# STM32WB55xx register map
File version: 1.0
Registers are 32-bit, read-write, reset 0x0 unless marked. A register's access mark holds for its fields unless they carry their own. Offsets are from the block's base; [hi:lo] are bit positions; {n}, {i} and the like mark numbered series.

## IPCC — Inter-Processor Communication
Base 0x58000C00
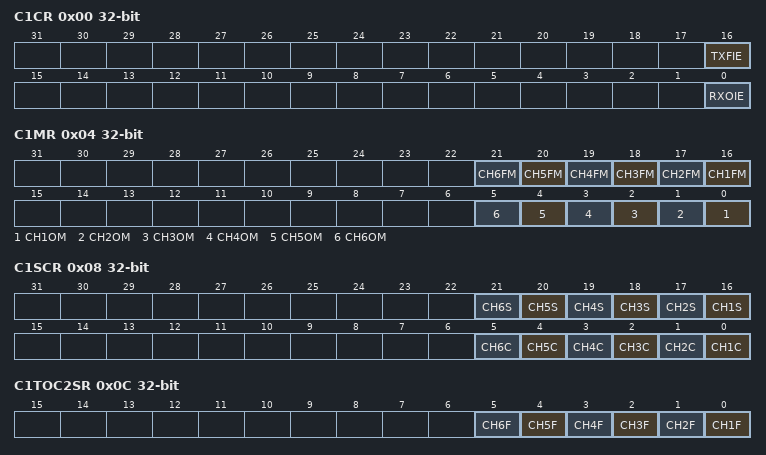
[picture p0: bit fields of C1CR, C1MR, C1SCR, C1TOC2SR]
0x00 C1CR — Inter-Processor Communication: C1 control register
  [16] TXFIE — Processor M4 Transmit channel free interrupt enable
  [0] RXOIE — Processor M4 Receive channel occupied interrupt enable
0x04 C1MR — Inter-Processor Communication: C1 mask register
  [n+15] CH{n}FM (n=1..6) — M4 Transmit Channel{n} free interrupt mask
  [n-1] CH{n}OM (n=1..6) — M4 Channel{n} occupied interrupt mask
0x08 C1SCR — Inter-Processor Communication: C1 status set clear register
  [n+15] CH{n}S (n=1..6) — M4 transmit Channel{n} status set
  [n-1] CH{n}C (n=1..6) — M4 receive Channel{n} status clear
0x0C C1TOC2SR — Inter-Processor Communication: C1 to processor M4 status register
  [n-1] CH{n}F (n=1..6) — M4 transmit to M4 receive Channel{n} status flag before masking
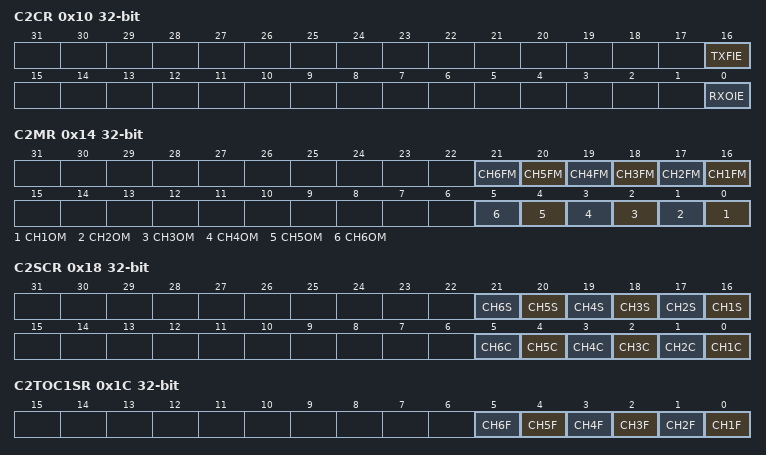
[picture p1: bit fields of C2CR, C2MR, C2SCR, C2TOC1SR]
0x10 C2CR — Inter-Processor Communication: C2 control register
  [16] TXFIE — Processor M0+ Transmit channel free interrupt enable
  [0] RXOIE — Processor M0+ Receive channel occupied interrupt enable
0x14 C2MR — Inter-Processor Communication: C2 mask register
  [n+15] CH{n}FM (n=1..6) — M0+ Transmit Channel{n} free interrupt mask
  [n-1] CH{n}OM (n=1..6) — M0+ Channel{n} occupied interrupt mask
0x18 C2SCR — Inter-Processor Communication: C2 status set clear register
  [n+15] CH{n}S (n=1..6) — M0+ transmit Channel{n} status set
  [n-1] CH{n}C (n=1..6) — M0+ receive Channel{n} status clear
0x1C C2TOC1SR — Inter-Processor Communication: C2 to processor M4 status register
  [n-1] CH{n}F (n=1..6) — M0+ transmit to M0 receive Channel{n} status flag before masking

## RNG
Base 0x58001000
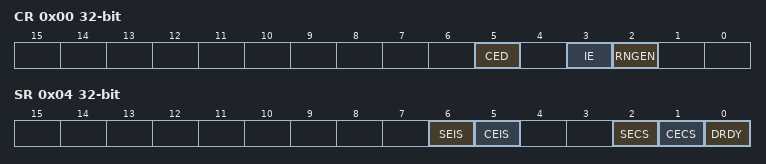
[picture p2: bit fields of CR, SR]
0x00 CR — RNG control register
  [5] CED, [3] IE, [2] RNGEN
0x04 SR — RNG status register
  [6] SEIS, [5] CEIS, [2] SECS, [1] CECS, [0] DRDY
0x08 DR — RNG data register

## HSEM — HW Semaphore HSEM
Base 0x58001400
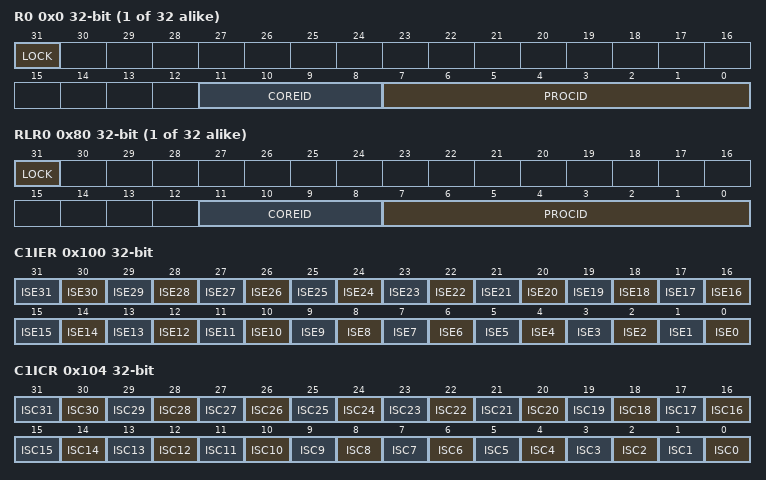
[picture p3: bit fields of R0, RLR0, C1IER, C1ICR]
{0x0+4i} R{i} (i=0..31) — HSEM 2-step write lock and read back registers
  [31] LOCK — Lock indication
  [11:8] COREID — Semaphore CoreID
    0=NONE; 4=CPU1; 8=CPU2
  [7:0] PROCID — Semaphore ProcessID
{0x80+4i} RLR{i} (i=0..31) — HSEM 1-step read lock registers
  [31] LOCK — Lock indication
  [11:8] COREID — Semaphore CoreID
  [7:0] PROCID — Semaphore ProcessID
0x100 C1IER — HSEM CPU1 interrupt enable register
  [n] ISE{n} (n=0..31) — semaphore {n} CPU1 interrupt enable bit
0x104 C1ICR — HSEM CPU1 interrupt clear register
  [n] ISC{n} (n=0..31) — semaphore {n} CPU1 interrupt clear bit
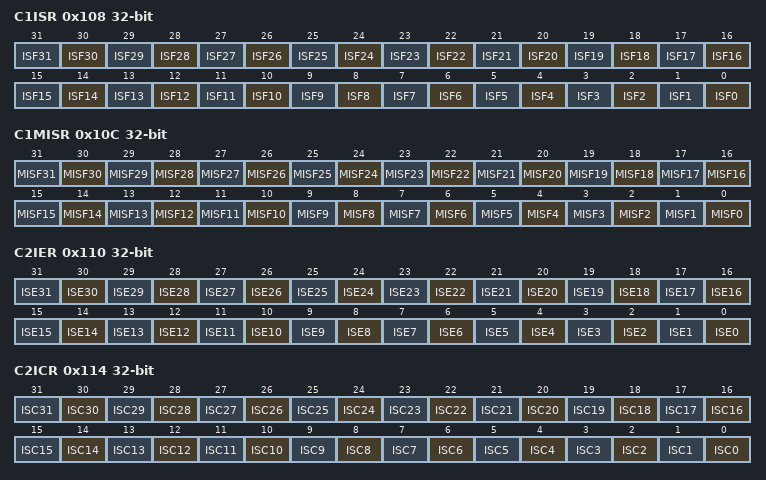
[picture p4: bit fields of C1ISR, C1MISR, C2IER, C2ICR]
0x108 C1ISR — HSEM CPU1 interrupt status register
  [n] ISF{n} (n=0..31) — semaphore {n} CPU1 interrupt status bit
0x10C C1MISR — HSEM CPU1 masked interrupt status register
  [n] MISF{n} (n=0..31) — semaphore {n} CPU1 interrupt masked status bit
0x110 C2IER — HSEM CPU2 interrupt enable register
  [n] ISE{n} (n=0..31) — semaphore {n} CPU2 interrupt enable bit
0x114 C2ICR — HSEM CPU2 interrupt clear register
  [n] ISC{n} (n=0..31) — semaphore {n} CPU2 interrupt clear bit
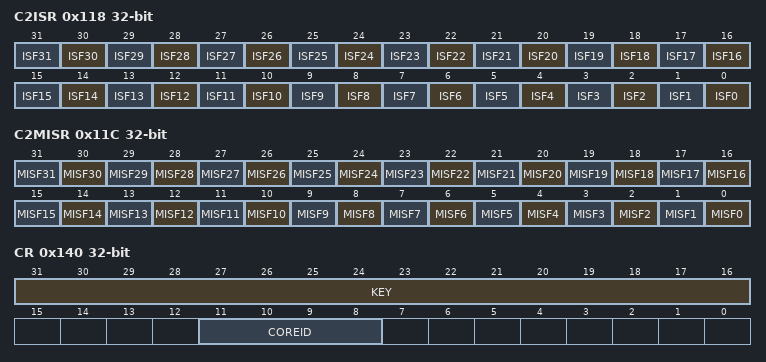
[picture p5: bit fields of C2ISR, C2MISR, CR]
0x118 C2ISR — HSEM CPU2 interrupt status register
  [n] ISF{n} (n=0..31) — semaphore {n} CPU2 interrupt status bit
0x11C C2MISR — HSEM CPU2 masked interrupt status register
  [n] MISF{n} (n=0..31) — semaphore {n} CPU2 interrupt masked status bit
0x140 CR — HSEM Semaphore clear register
  [31:16] KEY — semaphores clear key
  [11:8] COREID — CoreID of semaphores to be cleared
0x144 KEYR — HSEM Semaphore clear key register
  [31:16] KEY — semaphores clear key

## PKA — Public Key Accelerator (PKA)
Base 0x58002000
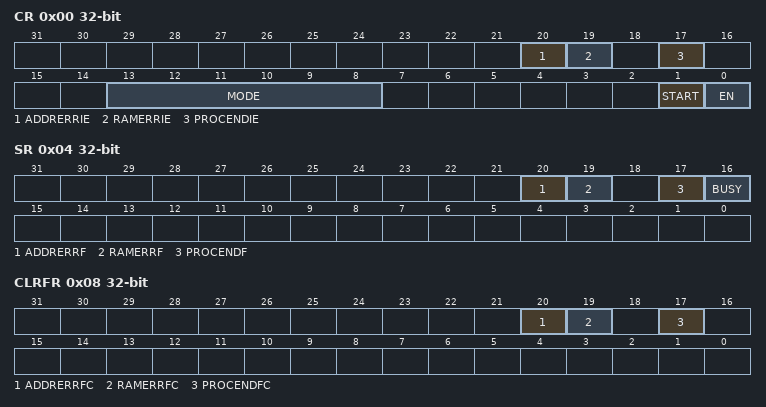
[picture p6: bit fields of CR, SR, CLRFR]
0x00 CR — PKA control register
  [20] ADDRERRIE — RAM error interrupt enable
  [19] RAMERRIE — RAM error interrupt enable
  [17] PROCENDIE — End of operation interrupt enable
  [13:8] MODE — MODE[5:0] PKA operation code
  [1] START — Start operation
  [0] EN — PKA enable
0x04 SR — PKA status register
  [20] ADDRERRF — Address error flag
  [19] RAMERRF — PKA RAM error flag
  [17] PROCENDF — PKA end of operation flag
  [16] BUSY — PKA operation is in progress
0x08 CLRFR — PKA clear flag register
  [20] ADDRERRFC — Clear address error flag
  [19] RAMERRFC — Clear PKA RAM error flag
  [17] PROCENDFC — Clear PKA end of operation flag
{0x400+4i} RAM[{i}] (i=0..893)

## QUADSPI — QUAD Serial Peripheral Interface
Base 0xA0001000
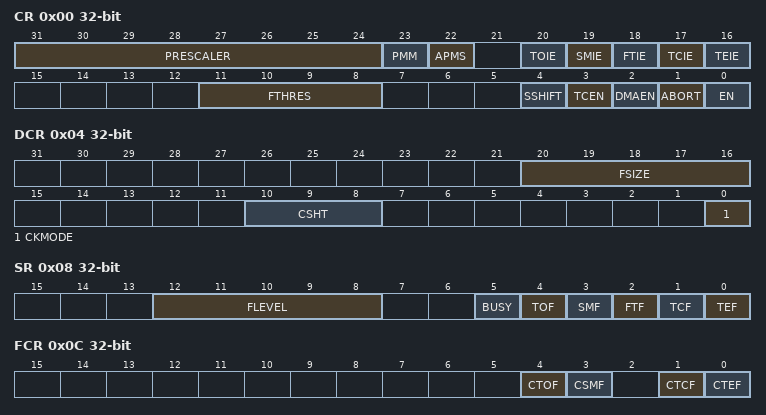
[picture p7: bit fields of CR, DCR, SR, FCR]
0x00 CR — QUADSPI Control register
  [31:24] PRESCALER — PRESCALER[7:0] Clock prescaler
  [23] PMM — Polling Match Mode
  [22] APMS — Automatic Polling Mode Stop
  [20] TOIE — TimeOut Interrupt Enable
  [19] SMIE — Status Match Interrupt Enable
  [18] FTIE — FIFO Threshold Interrupt Enable
  [17] TCIE — Transfer Complete Interrupt Enable
  [16] TEIE — Transfer Error Interrupt Enable
  [11:8] FTHRES — FTHRES[3:0] FIFO Level
  [4] SSHIFT — Sample Shift
  [3] TCEN — Timeout Counter Enable
  [2] DMAEN — DMA Enable
  [1] ABORT — Abort request
  [0] EN — Enable
0x04 DCR — QUADSPI Device Configuration register
  [20:16] FSIZE — FSIZE[4:0]: Flash Size
  [10:8] CSHT — CSHT[2:0]: ChipSelect High Time
  [0] CKMODE — Mode 0 / Mode 3
0x08 SR — QUADSPI Status register
  [12:8] FLEVEL — FIFO Threshlod Flag
  [5] BUSY
  [4] TOF — Timeout Flag
  [3] SMF — Status Match Flag
  [2] FTF — FIFO Threshlod Flag
  [1] TCF — Transfer Complete Flag
  [0] TEF — Transfer Error Flag
0x0C FCR — QUADSPI Flag Clear register
  [4] CTOF — Clear Timeout Flag
  [3] CSMF — Clear Status Match Flag
  [1] CTCF — Clear Transfer Complete Flag
  [0] CTEF — Clear Transfer Error Flag
0x10 DLR — QUADSPI Data Length register
  [31:0] DL — DL[31:0]: Data Length
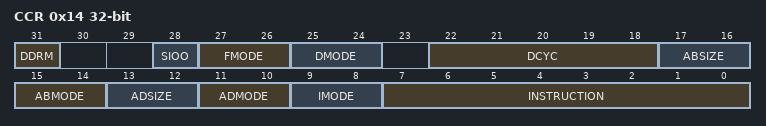
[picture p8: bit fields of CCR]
0x14 CCR — QUADSPI Communication Configuration register
  [31] DDRM — DDRM: Double Data Rate Mode
  [28] SIOO — SIOO: Send Instruction Only Once Mode
  [27:26] FMODE — FMODE[1:0]: Functional Mode
  [25:24] DMODE — DMODE[1:0]: Data Mode
  [22:18] DCYC — DCYC[4:0]: Dummy Cycles
  [17:16] ABSIZE — ABSIZE[1:0]: Instruction Mode
  [15:14] ABMODE — ABMODE[1:0]: Alternate Bytes Mode
  [13:12] ADSIZE — ADSIZE[1:0]: Address Size
  [11:10] ADMODE — ADMODE[1:0]: Address Mode
  [9:8] IMODE — IMODE[1:0]: Instruction Mode
  [7:0] INSTRUCTION — INSTRUCTION[7:0]: Instruction
0x18 AR — QUADSPI Address register
  [31:0] ADDRESS — ADDRESS[31:0]: Address
0x1C ABR — QUADSPI Alternate Bytes register
  [31:0] ALTERNATE — ALTERNATE[31:0]: Alternate Bytes
0x20 DR — QUADSPI Data register
  [31:0] DATA — DATA[31:0]: Data
0x24 PSMKR — QUADSPI Polling Status Mask register
  [31:0] MASK — MASK[31:0]: Status Mask
0x28 PSMAR — QUADSPI Polling Status Match register
  [31:0] MATCH — MATCH[31:0]: Status Match
0x2C PIR — QUADSPI Polling Interval register
  [15:0] INTERVAL — INTERVAL[15:0]: Polling Interval
0x30 LPTR — QUADSPI Low Power Timeout register
  [15:0] TIMEOUT — TIMEOUT[15:0]: Timeout period

## DBGMCU — Debug MCU
Base 0xE0042000
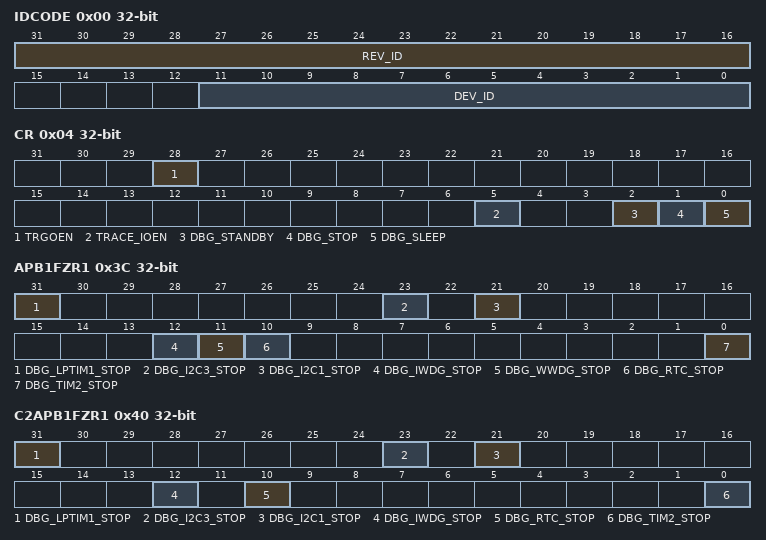
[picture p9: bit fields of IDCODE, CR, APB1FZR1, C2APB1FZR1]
0x00 IDCODE — MCU device ID code
  [31:16] REV_ID, [11:0] DEV_ID
0x04 CR — Debug MCU configuration register
  [28] TRGOEN, [5] TRACE_IOEN, [2] DBG_STANDBY, [1] DBG_STOP, [0] DBG_SLEEP
0x3C APB1FZR1 — Debug MCU CPU1 APB1 freeze register
  [31] DBG_LPTIM1_STOP, [23] DBG_I2C3_STOP, [21] DBG_I2C1_STOP, [12] DBG_IWDG_STOP, [11] DBG_WWDG_STOP, [10] DBG_RTC_STOP, [0] DBG_TIM2_STOP
0x40 C2APB1FZR1 — Debug MCU CPU2 APB1 freeze register
  [31] DBG_LPTIM1_STOP, [23] DBG_I2C3_STOP, [21] DBG_I2C1_STOP, [12] DBG_IWDG_STOP, [10] DBG_RTC_STOP, [0] DBG_TIM2_STOP
0x44 APB1FZR2 — Debug MCU CPU1 APB1 freeze register
  [5] DBG_LPTIM2_STOP
0x48 C2APB1FZR2 — Debug MCU CPU2 APB1 freeze register
  [5] DBG_LPTIM2_STOP
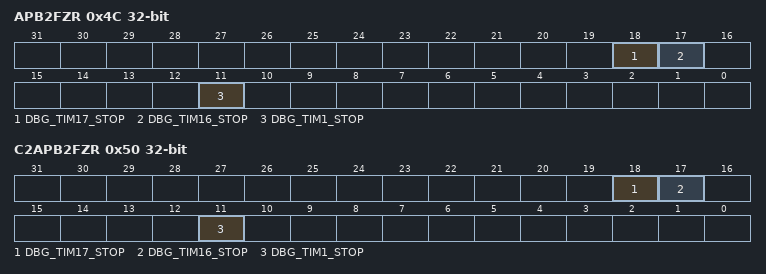
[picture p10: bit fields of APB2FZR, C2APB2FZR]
0x4C APB2FZR — Debug MCU CPU1 APB2 freeze register
  [18] DBG_TIM17_STOP, [17] DBG_TIM16_STOP, [11] DBG_TIM1_STOP
0x50 C2APB2FZR — Debug MCU CPU2 APB2 freeze register
  [18] DBG_TIM17_STOP, [17] DBG_TIM16_STOP, [11] DBG_TIM1_STOP
